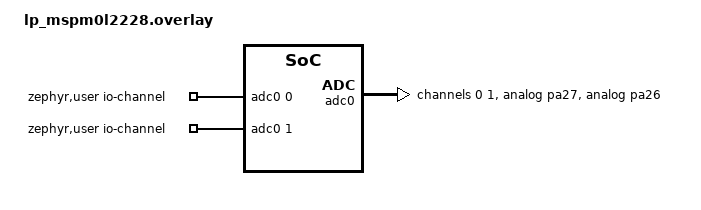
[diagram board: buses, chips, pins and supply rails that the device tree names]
/*
 * Copyright (c) 2026 Texas Instruments
 *
 * SPDX-License-Identifier: Apache-2.0
 */

#include <zephyr/dt-bindings/adc/adc.h>

/ {
	zephyr,user {
		io-channels = <&adc0 0>, <&adc0 1>;
	};
};

&adc0 {
	clocks = <&ckm MSPM0_CLOCK_ULPCLK>;
	ti,clk-divider = <1>;
	ti,clk-range = <6>;
	max-result-reg = <12>;
	pinctrl-0 = <&analog_pa27 &analog_pa26>;
	pinctrl-names = "default";
	status = "okay";
	#address-cells = <1>;
	#size-cells = <0>;

	channel@0 {
		reg = <0>;
		zephyr,gain = "ADC_GAIN_1";
		zephyr,reference = "ADC_REF_VDD_1";
		zephyr,acquisition-time = <ADC_ACQ_TIME_DEFAULT>;
		zephyr,resolution = <12>;
	};

	channel@1 {
		reg = <1>;
		zephyr,gain = "ADC_GAIN_1";
		zephyr,reference = "ADC_REF_VDD_1";
		zephyr,acquisition-time = <ADC_ACQ_TIME_DEFAULT>;
		zephyr,resolution = <12>;
	};
};
